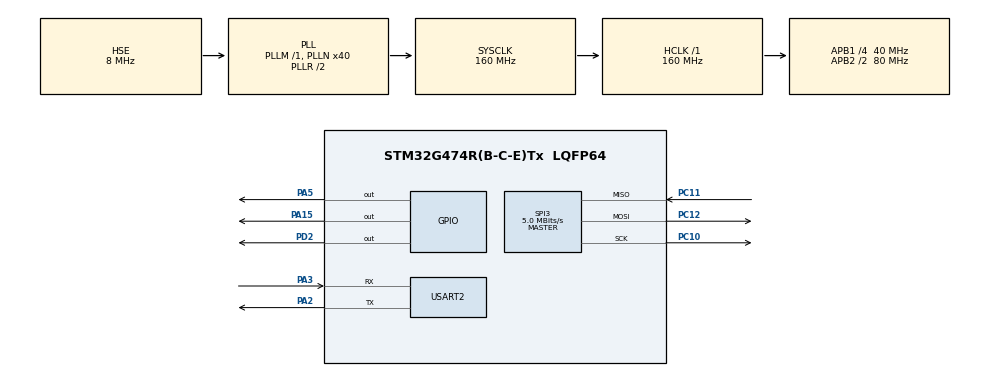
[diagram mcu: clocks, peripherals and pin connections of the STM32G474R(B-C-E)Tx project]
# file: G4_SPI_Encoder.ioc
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Mcu.Family=STM32G4
Mcu.Name=STM32G474R(B-C-E)Tx
Mcu.Package=LQFP64
NVIC.PriorityGroup=NVIC_PRIORITYGROUP_4
NVIC.USART2_IRQn=true\:0\:0\:false\:false\:true\:true\:true\:true
PA15.Signal=GPIO_Output
PA2.Mode=Asynchronous
PA2.Signal=USART2_TX
PA3.Mode=Asynchronous
PA3.Signal=USART2_RX
PA5.Signal=GPIO_Output
PC10.GPIO_PuPd=GPIO_PULLUP
PC10.Mode=Full_Duplex_Master
PC10.Signal=SPI3_SCK
PC11.GPIO_PuPd=GPIO_NOPULL
PC11.Mode=Full_Duplex_Master
PC11.Signal=SPI3_MISO
PC12.GPIO_PuPd=GPIO_NOPULL
PC12.Mode=Full_Duplex_Master
PC12.Signal=SPI3_MOSI
PD2.Signal=GPIO_Output
PF0-OSC_IN.Mode=HSE-External-Oscillator
PF0-OSC_IN.Signal=RCC_OSC_IN
PF1-OSC_OUT.Mode=HSE-External-Oscillator
PF1-OSC_OUT.Signal=RCC_OSC_OUT
ProjectManager.HeapSize=0x200
ProjectManager.StackSize=0x400
ProjectManager.TargetToolchain=STM32CubeIDE
RCC.ADC12Freq_Value=160000000
RCC.ADC345Freq_Value=160000000
RCC.AHBFreq_Value=160000000
RCC.APB1CLKDivider=RCC_HCLK_DIV4
RCC.APB1Freq_Value=40000000
RCC.APB1TimFreq_Value=80000000
RCC.APB2CLKDivider=RCC_HCLK_DIV2
RCC.APB2Freq_Value=80000000
RCC.APB2TimFreq_Value=160000000
RCC.CortexFreq_Value=160000000
RCC.EXTERNAL_CLOCK_VALUE=12288000
RCC.HCLKFreq_Value=160000000
RCC.HSE_VALUE=8000000
RCC.HSI48_VALUE=48000000
RCC.HSI_VALUE=16000000
RCC.LSE_VALUE=32768
RCC.PLLN=40
RCC.PLLSourceVirtual=RCC_PLLSOURCE_HSE
RCC.SYSCLKFreq_VALUE=160000000
RCC.SYSCLKSource=RCC_SYSCLKSOURCE_PLLCLK
RCC.USBFreq_Value=160000000
RCC.VCOOutputFreq_Value=320000000
SPI3.BaudRatePrescaler=SPI_BAUDRATEPRESCALER_8
SPI3.CLKPhase=SPI_PHASE_2EDGE
SPI3.CalculateBaudRate=5.0 MBits/s
SPI3.DataSize=SPI_DATASIZE_16BIT
SPI3.Direction=SPI_DIRECTION_2LINES
SPI3.Mode=SPI_MODE_MASTER
SPI3.VirtualType=VM_MASTER
USART2.VirtualMode-Asynchronous=VM_ASYNC
board=custom

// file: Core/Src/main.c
/* USER CODE BEGIN Header */
/**
  ******************************************************************************
  * @file           : main.c
  * @brief          : Main program body
  ******************************************************************************
  * @attention
  *
  * Copyright (c) 2023 STMicroelectronics.
  * All rights reserved.
  *
  * This software is licensed under terms that can be found in the LICENSE file
  * in the root directory of this software component.
  * If no LICENSE file comes with this software, it is provided AS-IS.
  *
  ******************************************************************************
  */
/* USER CODE END Header */
#include "main.h"
#include "spi.h"
#include "usart.h"
#include "gpio.h"

/* USER CODE BEGIN Includes */
#include "as50xx.h"
/* USER CODE END Includes */

void SystemClock_Config(void);

int main(void)
{

  /* MCU Configuration--------------------------------------------------------*/

  /* Reset of all peripherals, Initializes the Flash interface and the Systick. */
  HAL_Init();

  /* Configure the system clock */
  SystemClock_Config();

  /* Initialize all configured peripherals */
  MX_GPIO_Init();
  MX_USART2_UART_Init();
  MX_SPI3_Init();
  /* USER CODE BEGIN 2 */

  uint16_t ang;
  uint8_t str[100];
  int i = 0;

  /* USER CODE END 2 */

  /* Infinite loop */
  /* USER CODE BEGIN WHILE */
  while (1)
  {

	  as50_readAngle(&ang, 100);
	  sprintf(str,"angle: %d \n \r ", ang);
	  HAL_UART_Transmit_IT(&huart2, str, 22);
	  HAL_Delay(100);
	  /*
	  i++;
	  if (i == 30)
		  {
		  	  i = 0;
			  as50_setZero(100);
			  HAL_GPIO_TogglePin(GPIOA, GPIO_PIN_5);
		  }
*/
    /* USER CODE END WHILE */

  }
}

void SystemClock_Config(void)
{
  RCC_OscInitTypeDef RCC_OscInitStruct = {0};
  RCC_ClkInitTypeDef RCC_ClkInitStruct = {0};

  /** Configure the main internal regulator output voltage
  */
  HAL_PWREx_ControlVoltageScaling(PWR_REGULATOR_VOLTAGE_SCALE1_BOOST);

  /** Initializes the RCC Oscillators according to the specified parameters
  * in the RCC_OscInitTypeDef structure.
  */
  RCC_OscInitStruct.OscillatorType = RCC_OSCILLATORTYPE_HSE;
  RCC_OscInitStruct.HSEState = RCC_HSE_ON;
  RCC_OscInitStruct.PLL.PLLState = RCC_PLL_ON;
  RCC_OscInitStruct.PLL.PLLSource = RCC_PLLSOURCE_HSE;
  RCC_OscInitStruct.PLL.PLLM = RCC_PLLM_DIV1;
  RCC_OscInitStruct.PLL.PLLN = 40;
  RCC_OscInitStruct.PLL.PLLP = RCC_PLLP_DIV2;
  RCC_OscInitStruct.PLL.PLLQ = RCC_PLLQ_DIV2;
  RCC_OscInitStruct.PLL.PLLR = RCC_PLLR_DIV2;
  if (HAL_RCC_OscConfig(&RCC_OscInitStruct) != HAL_OK)
  {
    Error_Handler();
  }

  /** Initializes the CPU, AHB and APB buses clocks
  */
  RCC_ClkInitStruct.ClockType = RCC_CLOCKTYPE_HCLK|RCC_CLOCKTYPE_SYSCLK
                              |RCC_CLOCKTYPE_PCLK1|RCC_CLOCKTYPE_PCLK2;
  RCC_ClkInitStruct.SYSCLKSource = RCC_SYSCLKSOURCE_PLLCLK;
  RCC_ClkInitStruct.AHBCLKDivider = RCC_SYSCLK_DIV1;
  RCC_ClkInitStruct.APB1CLKDivider = RCC_HCLK_DIV4;
  RCC_ClkInitStruct.APB2CLKDivider = RCC_HCLK_DIV2;

  if (HAL_RCC_ClockConfig(&RCC_ClkInitStruct, FLASH_LATENCY_4) != HAL_OK)
  {
    Error_Handler();
  }
}

void Error_Handler(void)
{
  __disable_irq();
  while (1)
  {
  }
}
